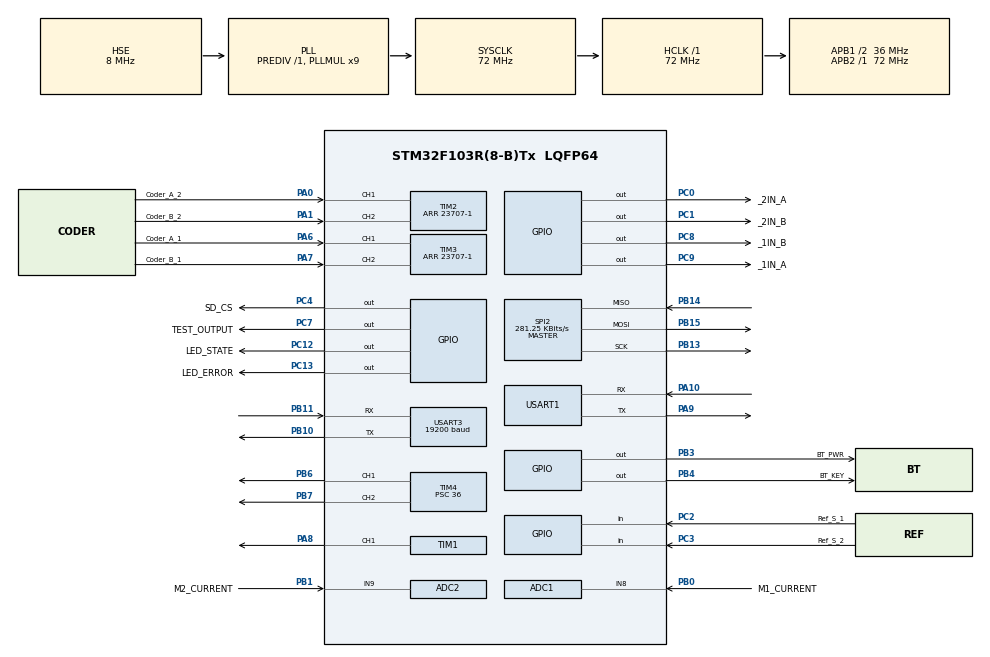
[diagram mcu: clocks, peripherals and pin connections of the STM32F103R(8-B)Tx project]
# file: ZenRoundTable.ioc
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ADC1.Channel-0\#ChannelRegularConversion=ADC_CHANNEL_8
ADC1.NbrOfConversion=1
ADC1.NbrOfConversionFlag=1
ADC1.Rank-0\#ChannelRegularConversion=1
ADC1.SamplingTime-0\#ChannelRegularConversion=ADC_SAMPLETIME_1CYCLE_5
ADC1.master=1
ADC2.Channel-0\#ChannelRegularConversion=ADC_CHANNEL_9
ADC2.NbrOfConversionFlag=1
ADC2.Rank-0\#ChannelRegularConversion=1
ADC2.SamplingTime-0\#ChannelRegularConversion=ADC_SAMPLETIME_1CYCLE_5
Dma.Request0=TIM1_CH1
Dma.TIM1_CH1.0.Direction=DMA_MEMORY_TO_PERIPH
Dma.TIM1_CH1.0.Instance=DMA1_Channel2
Dma.TIM1_CH1.0.MemDataAlignment=DMA_MDATAALIGN_HALFWORD
Dma.TIM1_CH1.0.MemInc=DMA_MINC_ENABLE
Dma.TIM1_CH1.0.Mode=DMA_NORMAL
Dma.TIM1_CH1.0.PeriphDataAlignment=DMA_PDATAALIGN_HALFWORD
Dma.TIM1_CH1.0.PeriphInc=DMA_PINC_DISABLE
Dma.TIM1_CH1.0.Priority=DMA_PRIORITY_LOW
Mcu.Family=STM32F1
Mcu.Name=STM32F103R(8-B)Tx
Mcu.Package=LQFP64
NVIC.DMA1_Channel2_IRQn=true\:0\:0\:false\:false\:true\:false\:true\:true
NVIC.PriorityGroup=NVIC_PRIORITYGROUP_4
NVIC.USART1_IRQn=true\:0\:0\:false\:false\:true\:true\:true\:true
NVIC.USART3_IRQn=true\:0\:0\:false\:false\:true\:true\:true\:true
PA0-WKUP.GPIO_Label=Coder_A_2
PA0-WKUP.Signal=S_TIM2_CH1_ETR
PA1.GPIO_Label=Coder_B_2
PA1.Signal=S_TIM2_CH2
PA10.Mode=Asynchronous
PA10.Signal=USART1_RX
PA13.Mode=Serial_Wire
PA13.Signal=SYS_JTMS-SWDIO
PA14.Mode=Serial_Wire
PA14.Signal=SYS_JTCK-SWCLK
PA6.GPIO_Label=Coder_A_1
PA6.Signal=S_TIM3_CH1
PA7.GPIO_Label=Coder_B_1
PA7.Signal=S_TIM3_CH2
PA8.Signal=S_TIM1_CH1
PA9.Mode=Asynchronous
PA9.Signal=USART1_TX
PB0.GPIO_Label=M1_CURRENT
PB0.Signal=ADCx_IN8
PB1.GPIO_Label=M2_CURRENT
PB1.Signal=ADCx_IN9
PB10.Mode=Asynchronous
PB10.Signal=USART3_TX
PB11.Mode=Asynchronous
PB11.Signal=USART3_RX
PB13.Mode=Full_Duplex_Master
PB13.Signal=SPI2_SCK
PB14.Mode=Full_Duplex_Master
PB14.Signal=SPI2_MISO
PB15.Mode=Full_Duplex_Master
PB15.Signal=SPI2_MOSI
PB3.GPIO_Label=BT_PWR
PB3.Signal=GPIO_Output
PB4.GPIO_Label=BT_KEY
PB4.Signal=GPIO_Output
PB6.Signal=S_TIM4_CH1
PB7.Signal=S_TIM4_CH2
PB8.Signal=I2C1_SCL
PB9.Signal=I2C1_SDA
PC0.GPIO_Label=_2IN_A
PC0.Signal=GPIO_Output
PC1.GPIO_Label=_2IN_B
PC1.Signal=GPIO_Output
PC12.GPIO_Label=LED_STATE
PC12.Signal=GPIO_Output
PC13-TAMPER-RTC.GPIO_Label=LED_ERROR
PC13-TAMPER-RTC.Signal=GPIO_Output
PC2.GPIO_Label=Ref_S_1
PC2.GPIO_PuPd=GPIO_PULLUP
PC2.Signal=GPIO_Input
PC3.GPIO_Label=Ref_S_2
PC3.GPIO_PuPd=GPIO_PULLUP
PC3.Signal=GPIO_Input
PC4.GPIO_Label=SD_CS
PC4.Signal=GPIO_Output
PC7.GPIO_Label=TEST_OUTPUT
PC7.Signal=GPIO_Output
PC8.GPIO_Label=_1IN_B
PC8.Signal=GPIO_Output
PC9.GPIO_Label=_1IN_A
PC9.Signal=GPIO_Output
PD0-OSC_IN.Mode=HSE-External-Oscillator
PD0-OSC_IN.Signal=RCC_OSC_IN
PD1-OSC_OUT.Mode=HSE-External-Oscillator
PD1-OSC_OUT.Signal=RCC_OSC_OUT
ProjectManager.HeapSize=0x200
ProjectManager.StackSize=0x400
ProjectManager.TargetToolchain=STM32CubeIDE
RCC.ADCPresc=RCC_ADCPCLK2_DIV6
RCC.AHBFreq_Value=72000000
RCC.APB1CLKDivider=RCC_HCLK_DIV2
RCC.APB1Freq_Value=36000000
RCC.APB1TimFreq_Value=72000000
RCC.APB2Freq_Value=72000000
RCC.APB2TimFreq_Value=72000000
RCC.HCLKFreq_Value=72000000
RCC.PLLMUL=RCC_PLL_MUL9
RCC.PLLSourceVirtual=RCC_PLLSOURCE_HSE
RCC.SYSCLKFreq_VALUE=72000000
RCC.SYSCLKSource=RCC_SYSCLKSOURCE_PLLCLK
RCC.USBFreq_Value=72000000
SH.ADCx_IN8.0=ADC1_IN8,IN8
SH.ADCx_IN9.0=ADC2_IN9,IN9
SH.S_TIM1_CH1.0=TIM1_CH1,PWM Generation1 CH1
SH.S_TIM2_CH1_ETR.0=TIM2_CH1,Encoder_Interface
SH.S_TIM2_CH2.0=TIM2_CH2,Encoder_Interface
SH.S_TIM3_CH1.0=TIM3_CH1,Encoder_Interface
SH.S_TIM3_CH2.0=TIM3_CH2,Encoder_Interface
SH.S_TIM4_CH1.0=TIM4_CH1,PWM Generation1 CH1
SH.S_TIM4_CH2.0=TIM4_CH2,PWM Generation2 CH2
SPI2.BaudRatePrescaler=SPI_BAUDRATEPRESCALER_128
SPI2.CalculateBaudRate=281.25 KBits/s
SPI2.Direction=SPI_DIRECTION_2LINES
SPI2.Mode=SPI_MODE_MASTER
SPI2.VirtualType=VM_MASTER
TIM1.Channel-PWM\ Generation1\ CH1=TIM_CHANNEL_1
TIM1.Period=90-1
TIM1.Pulse-PWM\ Generation1\ CH1=10
TIM2.CounterMode=TIM_COUNTERMODE_UP
TIM2.EncoderMode=TIM_ENCODERMODE_TI12
TIM2.IC1Polarity=TIM_ICPOLARITY_RISING
TIM2.IC2Polarity=TIM_ICPOLARITY_FALLING
TIM2.Period=23707-1
TIM3.EncoderMode=TIM_ENCODERMODE_TI12
TIM3.IC1Polarity=TIM_ICPOLARITY_RISING
TIM3.IC2Polarity=TIM_ICPOLARITY_RISING
TIM3.Period=23707-1
TIM4.Channel-PWM\ Generation1\ CH1=TIM_CHANNEL_1
TIM4.Channel-PWM\ Generation2\ CH2=TIM_CHANNEL_2
TIM4.Period=100
TIM4.Prescaler=36
USART1.VirtualMode=VM_ASYNC
USART3.BaudRate=19200
USART3.VirtualMode=VM_ASYNC
VP_FATFS_VS_Generic.Mode=User_defined
VP_TIM1_VS_ClockSourceINT.Mode=Internal
board=custom

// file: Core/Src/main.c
/* USER CODE BEGIN Header */
/**
  ******************************************************************************
  * @file           : main.c
  * @brief          : Main program body
  ******************************************************************************
  * @attention
  *
  * Copyright (c) 2024 STMicroelectronics.
  * All rights reserved.
  *
  * This software is licensed under terms that can be found in the LICENSE file
  * in the root directory of this software component.
  * If no LICENSE file comes with this software, it is provided AS-IS.
  *
  ******************************************************************************
  */
/* USER CODE END Header */
#include "main.h"
#include "fatfs.h"

ADC_HandleTypeDef hadc1;
ADC_HandleTypeDef hadc2;

SPI_HandleTypeDef hspi2;

TIM_HandleTypeDef htim1;
TIM_HandleTypeDef htim2;
TIM_HandleTypeDef htim3;
TIM_HandleTypeDef htim4;
DMA_HandleTypeDef hdma_tim1_ch1;

UART_HandleTypeDef huart1;
UART_HandleTypeDef huart3;

void SystemClock_Config(void);
static void MX_GPIO_Init(void);
static void MX_DMA_Init(void);
static void MX_SPI2_Init(void);
static void MX_TIM2_Init(void);
static void MX_TIM3_Init(void);
static void MX_TIM4_Init(void);
static void MX_USART1_UART_Init(void);
static void MX_USART3_UART_Init(void);
static void MX_ADC1_Init(void);
static void MX_ADC2_Init(void);
static void MX_TIM1_Init(void);
/* USER CODE BEGIN PFP */
void main_user();
/* USER CODE END PFP */

int main(void)
{

  /* MCU Configuration--------------------------------------------------------*/

  /* Reset of all peripherals, Initializes the Flash interface and the Systick. */
  HAL_Init();

  /* Configure the system clock */
  SystemClock_Config();

  /* Initialize all configured peripherals */
  MX_GPIO_Init();
  MX_DMA_Init();
  MX_SPI2_Init();
  MX_TIM2_Init();
  MX_TIM3_Init();
  MX_TIM4_Init();
  MX_USART1_UART_Init();
  MX_USART3_UART_Init();
  MX_FATFS_Init();
  MX_ADC1_Init();
  MX_ADC2_Init();
  MX_TIM1_Init();
  /* USER CODE BEGIN 2 */
  main_user();
  /* USER CODE END 2 */

  /* Infinite loop */
  while (1)
  {

    /* USER CODE BEGIN 3 */

	  HAL_GPIO_TogglePin (LED_STATE_GPIO_Port,LED_STATE_Pin);
	  HAL_GPIO_TogglePin (LED_ERROR_GPIO_Port,LED_ERROR_Pin);
	  HAL_GPIO_TogglePin (TEST_OUTPUT_GPIO_Port,TEST_OUTPUT_Pin);

	  //printf("Hello World, this brubs Application!\n");
	  HAL_Delay (750);

  }
  /* USER CODE END 3 */
}

void SystemClock_Config(void)
{
  RCC_OscInitTypeDef RCC_OscInitStruct = {0};
  RCC_ClkInitTypeDef RCC_ClkInitStruct = {0};
  RCC_PeriphCLKInitTypeDef PeriphClkInit = {0};

  /** Initializes the RCC Oscillators according to the specified parameters
  * in the RCC_OscInitTypeDef structure.
  */
  RCC_OscInitStruct.OscillatorType = RCC_OSCILLATORTYPE_HSE;
  RCC_OscInitStruct.HSEState = RCC_HSE_ON;
  RCC_OscInitStruct.HSEPredivValue = RCC_HSE_PREDIV_DIV1;
  RCC_OscInitStruct.HSIState = RCC_HSI_ON;
  RCC_OscInitStruct.PLL.PLLState = RCC_PLL_ON;
  RCC_OscInitStruct.PLL.PLLSource = RCC_PLLSOURCE_HSE;
  RCC_OscInitStruct.PLL.PLLMUL = RCC_PLL_MUL9;
  if (HAL_RCC_OscConfig(&RCC_OscInitStruct) != HAL_OK)
  {
    Error_Handler();
  }

  /** Initializes the CPU, AHB and APB buses clocks
  */
  RCC_ClkInitStruct.ClockType = RCC_CLOCKTYPE_HCLK|RCC_CLOCKTYPE_SYSCLK
                              |RCC_CLOCKTYPE_PCLK1|RCC_CLOCKTYPE_PCLK2;
  RCC_ClkInitStruct.SYSCLKSource = RCC_SYSCLKSOURCE_PLLCLK;
  RCC_ClkInitStruct.AHBCLKDivider = RCC_SYSCLK_DIV1;
  RCC_ClkInitStruct.APB1CLKDivider = RCC_HCLK_DIV2;
  RCC_ClkInitStruct.APB2CLKDivider = RCC_HCLK_DIV1;

  if (HAL_RCC_ClockConfig(&RCC_ClkInitStruct, FLASH_LATENCY_2) != HAL_OK)
  {
    Error_Handler();
  }
  PeriphClkInit.PeriphClockSelection = RCC_PERIPHCLK_ADC;
  PeriphClkInit.AdcClockSelection = RCC_ADCPCLK2_DIV6;
  if (HAL_RCCEx_PeriphCLKConfig(&PeriphClkInit) != HAL_OK)
  {
    Error_Handler();
  }
}

static void MX_ADC1_Init(void)
{

  ADC_ChannelConfTypeDef sConfig = {0};

  /** Common config
  */
  hadc1.Instance = ADC1;
  hadc1.Init.ScanConvMode = ADC_SCAN_DISABLE;
  hadc1.Init.ContinuousConvMode = DISABLE;
  hadc1.Init.DiscontinuousConvMode = DISABLE;
  hadc1.Init.ExternalTrigConv = ADC_SOFTWARE_START;
  hadc1.Init.DataAlign = ADC_DATAALIGN_RIGHT;
  hadc1.Init.NbrOfConversion = 1;
  if (HAL_ADC_Init(&hadc1) != HAL_OK)
  {
    Error_Handler();
  }

  /** Configure Regular Channel
  */
  sConfig.Channel = ADC_CHANNEL_8;
  sConfig.Rank = ADC_REGULAR_RANK_1;
  sConfig.SamplingTime = ADC_SAMPLETIME_1CYCLE_5;
  if (HAL_ADC_ConfigChannel(&hadc1, &sConfig) != HAL_OK)
  {
    Error_Handler();
  }

}

static void MX_ADC2_Init(void)
{

  ADC_ChannelConfTypeDef sConfig = {0};

  /** Common config
  */
  hadc2.Instance = ADC2;
  hadc2.Init.ScanConvMode = ADC_SCAN_DISABLE;
  hadc2.Init.ContinuousConvMode = DISABLE;
  hadc2.Init.DiscontinuousConvMode = DISABLE;
  hadc2.Init.ExternalTrigConv = ADC_SOFTWARE_START;
  hadc2.Init.DataAlign = ADC_DATAALIGN_RIGHT;
  hadc2.Init.NbrOfConversion = 1;
  if (HAL_ADC_Init(&hadc2) != HAL_OK)
  {
    Error_Handler();
  }

  /** Configure Regular Channel
  */
  sConfig.Channel = ADC_CHANNEL_9;
  sConfig.Rank = ADC_REGULAR_RANK_1;
  sConfig.SamplingTime = ADC_SAMPLETIME_1CYCLE_5;
  if (HAL_ADC_ConfigChannel(&hadc2, &sConfig) != HAL_OK)
  {
    Error_Handler();
  }

}

static void MX_SPI2_Init(void)
{

  /* SPI2 parameter configuration*/
  hspi2.Instance = SPI2;
  hspi2.Init.Mode = SPI_MODE_MASTER;
  hspi2.Init.Direction = SPI_DIRECTION_2LINES;
  hspi2.Init.DataSize = SPI_DATASIZE_8BIT;
  hspi2.Init.CLKPolarity = SPI_POLARITY_LOW;
  hspi2.Init.CLKPhase = SPI_PHASE_1EDGE;
  hspi2.Init.NSS = SPI_NSS_SOFT;
  hspi2.Init.BaudRatePrescaler = SPI_BAUDRATEPRESCALER_128;
  hspi2.Init.FirstBit = SPI_FIRSTBIT_MSB;
  hspi2.Init.TIMode = SPI_TIMODE_DISABLE;
  hspi2.Init.CRCCalculation = SPI_CRCCALCULATION_DISABLE;
  hspi2.Init.CRCPolynomial = 10;
  if (HAL_SPI_Init(&hspi2) != HAL_OK)
  {
    Error_Handler();
  }

}

static void MX_TIM1_Init(void)
{

  TIM_ClockConfigTypeDef sClockSourceConfig = {0};
  TIM_MasterConfigTypeDef sMasterConfig = {0};
  TIM_OC_InitTypeDef sConfigOC = {0};
  TIM_BreakDeadTimeConfigTypeDef sBreakDeadTimeConfig = {0};

  htim1.Instance = TIM1;
  htim1.Init.Prescaler = 0;
  htim1.Init.CounterMode = TIM_COUNTERMODE_UP;
  htim1.Init.Period = 90-1;
  htim1.Init.ClockDivision = TIM_CLOCKDIVISION_DIV1;
  htim1.Init.RepetitionCounter = 0;
  htim1.Init.AutoReloadPreload = TIM_AUTORELOAD_PRELOAD_DISABLE;
  if (HAL_TIM_Base_Init(&htim1) != HAL_OK)
  {
    Error_Handler();
  }
  sClockSourceConfig.ClockSource = TIM_CLOCKSOURCE_INTERNAL;
  if (HAL_TIM_ConfigClockSource(&htim1, &sClockSourceConfig) != HAL_OK)
  {
    Error_Handler();
  }
  if (HAL_TIM_PWM_Init(&htim1) != HAL_OK)
  {
    Error_Handler();
  }
  sMasterConfig.MasterOutputTrigger = TIM_TRGO_RESET;
  sMasterConfig.MasterSlaveMode = TIM_MASTERSLAVEMODE_DISABLE;
  if (HAL_TIMEx_MasterConfigSynchronization(&htim1, &sMasterConfig) != HAL_OK)
  {
    Error_Handler();
  }
  sConfigOC.OCMode = TIM_OCMODE_PWM1;
  sConfigOC.Pulse = 10;
  sConfigOC.OCPolarity = TIM_OCPOLARITY_HIGH;
  sConfigOC.OCNPolarity = TIM_OCNPOLARITY_HIGH;
  sConfigOC.OCFastMode = TIM_OCFAST_DISABLE;
  sConfigOC.OCIdleState = TIM_OCIDLESTATE_RESET;
  sConfigOC.OCNIdleState = TIM_OCNIDLESTATE_RESET;
  if (HAL_TIM_PWM_ConfigChannel(&htim1, &sConfigOC, TIM_CHANNEL_1) != HAL_OK)
  {
    Error_Handler();
  }
  sBreakDeadTimeConfig.OffStateRunMode = TIM_OSSR_DISABLE;
  sBreakDeadTimeConfig.OffStateIDLEMode = TIM_OSSI_DISABLE;
  sBreakDeadTimeConfig.LockLevel = TIM_LOCKLEVEL_OFF;
  sBreakDeadTimeConfig.DeadTime = 0;
  sBreakDeadTimeConfig.BreakState = TIM_BREAK_DISABLE;
  sBreakDeadTimeConfig.BreakPolarity = TIM_BREAKPOLARITY_HIGH;
  sBreakDeadTimeConfig.AutomaticOutput = TIM_AUTOMATICOUTPUT_DISABLE;
  if (HAL_TIMEx_ConfigBreakDeadTime(&htim1, &sBreakDeadTimeConfig) != HAL_OK)
  {
    Error_Handler();
  }
  HAL_TIM_MspPostInit(&htim1);

}

static void MX_TIM2_Init(void)
{

  TIM_Encoder_InitTypeDef sConfig = {0};
  TIM_MasterConfigTypeDef sMasterConfig = {0};

  htim2.Instance = TIM2;
  htim2.Init.Prescaler = 0;
  htim2.Init.CounterMode = TIM_COUNTERMODE_UP;
  htim2.Init.Period = 23707-1;
  htim2.Init.ClockDivision = TIM_CLOCKDIVISION_DIV1;
  htim2.Init.AutoReloadPreload = TIM_AUTORELOAD_PRELOAD_DISABLE;
  sConfig.EncoderMode = TIM_ENCODERMODE_TI12;
  sConfig.IC1Polarity = TIM_ICPOLARITY_RISING;
  sConfig.IC1Selection = TIM_ICSELECTION_DIRECTTI;
  sConfig.IC1Prescaler = TIM_ICPSC_DIV1;
  sConfig.IC1Filter = 0;
  sConfig.IC2Polarity = TIM_ICPOLARITY_FALLING;
  sConfig.IC2Selection = TIM_ICSELECTION_DIRECTTI;
  sConfig.IC2Prescaler = TIM_ICPSC_DIV1;
  sConfig.IC2Filter = 0;
  if (HAL_TIM_Encoder_Init(&htim2, &sConfig) != HAL_OK)
  {
    Error_Handler();
  }
  sMasterConfig.MasterOutputTrigger = TIM_TRGO_RESET;
  sMasterConfig.MasterSlaveMode = TIM_MASTERSLAVEMODE_DISABLE;
  if (HAL_TIMEx_MasterConfigSynchronization(&htim2, &sMasterConfig) != HAL_OK)
  {
    Error_Handler();
  }

}

static void MX_TIM3_Init(void)
{

  TIM_Encoder_InitTypeDef sConfig = {0};
  TIM_MasterConfigTypeDef sMasterConfig = {0};

  htim3.Instance = TIM3;
  htim3.Init.Prescaler = 0;
  htim3.Init.CounterMode = TIM_COUNTERMODE_UP;
  htim3.Init.Period = 23707-1;
  htim3.Init.ClockDivision = TIM_CLOCKDIVISION_DIV1;
  htim3.Init.AutoReloadPreload = TIM_AUTORELOAD_PRELOAD_DISABLE;
  sConfig.EncoderMode = TIM_ENCODERMODE_TI12;
  sConfig.IC1Polarity = TIM_ICPOLARITY_RISING;
  sConfig.IC1Selection = TIM_ICSELECTION_DIRECTTI;
  sConfig.IC1Prescaler = TIM_ICPSC_DIV1;
  sConfig.IC1Filter = 0;
  sConfig.IC2Polarity = TIM_ICPOLARITY_RISING;
  sConfig.IC2Selection = TIM_ICSELECTION_DIRECTTI;
  sConfig.IC2Prescaler = TIM_ICPSC_DIV1;
  sConfig.IC2Filter = 0;
  if (HAL_TIM_Encoder_Init(&htim3, &sConfig) != HAL_OK)
  {
    Error_Handler();
  }
  sMasterConfig.MasterOutputTrigger = TIM_TRGO_RESET;
  sMasterConfig.MasterSlaveMode = TIM_MASTERSLAVEMODE_DISABLE;
  if (HAL_TIMEx_MasterConfigSynchronization(&htim3, &sMasterConfig) != HAL_OK)
  {
    Error_Handler();
  }

}

static void MX_TIM4_Init(void)
{

  TIM_MasterConfigTypeDef sMasterConfig = {0};
  TIM_OC_InitTypeDef sConfigOC = {0};

  htim4.Instance = TIM4;
  htim4.Init.Prescaler = 36;
  htim4.Init.CounterMode = TIM_COUNTERMODE_UP;
  htim4.Init.Period = 100;
  htim4.Init.ClockDivision = TIM_CLOCKDIVISION_DIV1;
  htim4.Init.AutoReloadPreload = TIM_AUTORELOAD_PRELOAD_DISABLE;
  if (HAL_TIM_PWM_Init(&htim4) != HAL_OK)
  {
    Error_Handler();
  }
  sMasterConfig.MasterOutputTrigger = TIM_TRGO_RESET;
  sMasterConfig.MasterSlaveMode = TIM_MASTERSLAVEMODE_DISABLE;
  if (HAL_TIMEx_MasterConfigSynchronization(&htim4, &sMasterConfig) != HAL_OK)
  {
    Error_Handler();
  }
  sConfigOC.OCMode = TIM_OCMODE_PWM1;
  sConfigOC.Pulse = 0;
  sConfigOC.OCPolarity = TIM_OCPOLARITY_HIGH;
  sConfigOC.OCFastMode = TIM_OCFAST_DISABLE;
  if (HAL_TIM_PWM_ConfigChannel(&htim4, &sConfigOC, TIM_CHANNEL_1) != HAL_OK)
  {
    Error_Handler();
  }
  if (HAL_TIM_PWM_ConfigChannel(&htim4, &sConfigOC, TIM_CHANNEL_2) != HAL_OK)
  {
    Error_Handler();
  }
  HAL_TIM_MspPostInit(&htim4);

}

static void MX_USART1_UART_Init(void)
{

  huart1.Instance = USART1;
  huart1.Init.BaudRate = 115200;
  huart1.Init.WordLength = UART_WORDLENGTH_8B;
  huart1.Init.StopBits = UART_STOPBITS_1;
  huart1.Init.Parity = UART_PARITY_NONE;
  huart1.Init.Mode = UART_MODE_TX_RX;
  huart1.Init.HwFlowCtl = UART_HWCONTROL_NONE;
  huart1.Init.OverSampling = UART_OVERSAMPLING_16;
  if (HAL_UART_Init(&huart1) != HAL_OK)
  {
    Error_Handler();
  }

}

static void MX_USART3_UART_Init(void)
{

  huart3.Instance = USART3;
  huart3.Init.BaudRate = 19200;
  huart3.Init.WordLength = UART_WORDLENGTH_8B;
  huart3.Init.StopBits = UART_STOPBITS_1;
  huart3.Init.Parity = UART_PARITY_NONE;
  huart3.Init.Mode = UART_MODE_TX_RX;
  huart3.Init.HwFlowCtl = UART_HWCONTROL_NONE;
  huart3.Init.OverSampling = UART_OVERSAMPLING_16;
  if (HAL_UART_Init(&huart3) != HAL_OK)
  {
    Error_Handler();
  }

}

static void MX_DMA_Init(void)
{

  /* DMA controller clock enable */
  __HAL_RCC_DMA1_CLK_ENABLE();

  /* DMA interrupt init */
  /* DMA1_Channel2_IRQn interrupt configuration */
  HAL_NVIC_SetPriority(DMA1_Channel2_IRQn, 0, 0);
  HAL_NVIC_EnableIRQ(DMA1_Channel2_IRQn);

}

static void MX_GPIO_Init(void)
{
  GPIO_InitTypeDef GPIO_InitStruct = {0};

  /* GPIO Ports Clock Enable */
  __HAL_RCC_GPIOC_CLK_ENABLE();
  __HAL_RCC_GPIOD_CLK_ENABLE();
  __HAL_RCC_GPIOA_CLK_ENABLE();
  __HAL_RCC_GPIOB_CLK_ENABLE();

  /*Configure GPIO pin Output Level */
  HAL_GPIO_WritePin(GPIOC, LED_ERROR_Pin|_2IN_A_Pin|_2IN_B_Pin|SD_CS_Pin
                          |TEST_OUTPUT_Pin|_1IN_B_Pin|_1IN_A_Pin|LED_STATE_Pin, GPIO_PIN_RESET);

  /*Configure GPIO pin Output Level */
  HAL_GPIO_WritePin(GPIOB, BT_PWR_Pin|BT_KEY_Pin, GPIO_PIN_RESET);

  /*Configure GPIO pins : LED_ERROR_Pin _2IN_A_Pin _2IN_B_Pin SD_CS_Pin
                           TEST_OUTPUT_Pin _1IN_B_Pin _1IN_A_Pin LED_STATE_Pin */
  GPIO_InitStruct.Pin = LED_ERROR_Pin|_2IN_A_Pin|_2IN_B_Pin|SD_CS_Pin
                          |TEST_OUTPUT_Pin|_1IN_B_Pin|_1IN_A_Pin|LED_STATE_Pin;
  GPIO_InitStruct.Mode = GPIO_MODE_OUTPUT_PP;
  GPIO_InitStruct.Pull = GPIO_NOPULL;
  GPIO_InitStruct.Speed = GPIO_SPEED_FREQ_LOW;
  HAL_GPIO_Init(GPIOC, &GPIO_InitStruct);

  /*Configure GPIO pins : Ref_S_1_Pin Ref_S_2_Pin */
  GPIO_InitStruct.Pin = Ref_S_1_Pin|Ref_S_2_Pin;
  GPIO_InitStruct.Mode = GPIO_MODE_INPUT;
  GPIO_InitStruct.Pull = GPIO_PULLUP;
  HAL_GPIO_Init(GPIOC, &GPIO_InitStruct);

  /*Configure GPIO pins : BT_PWR_Pin BT_KEY_Pin */
  GPIO_InitStruct.Pin = BT_PWR_Pin|BT_KEY_Pin;
  GPIO_InitStruct.Mode = GPIO_MODE_OUTPUT_PP;
  GPIO_InitStruct.Pull = GPIO_NOPULL;
  GPIO_InitStruct.Speed = GPIO_SPEED_FREQ_LOW;
  HAL_GPIO_Init(GPIOB, &GPIO_InitStruct);

  /*Configure GPIO pins : PB8 PB9 */
  GPIO_InitStruct.Pin = GPIO_PIN_8|GPIO_PIN_9;
  GPIO_InitStruct.Mode = GPIO_MODE_AF_OD;
  GPIO_InitStruct.Speed = GPIO_SPEED_FREQ_HIGH;
  HAL_GPIO_Init(GPIOB, &GPIO_InitStruct);

  /*Configure peripheral I/O remapping */
  __HAL_AFIO_REMAP_I2C1_ENABLE();

}

void Error_Handler(void)
{
  __disable_irq();
  while (1)
  {
  }
}
